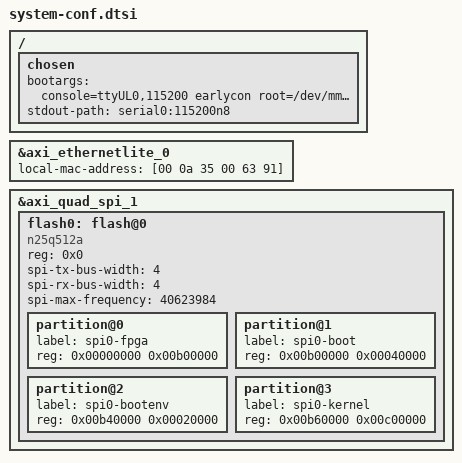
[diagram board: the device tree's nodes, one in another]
/*
 * CAUTION: This file is automatically generated by PetaLinux SDK.
 * DO NOT modify this file
 */


/ {
	chosen {
		bootargs = "console=ttyUL0,115200 earlycon root=/dev/mmcblk0p1 rw rootwait rootfstype=ext4";
		stdout-path = "serial0:115200n8";
	};
};

&axi_ethernetlite_0 {
	local-mac-address = [00 0a 35 00 63 91];
};

&axi_quad_spi_1 {
	#address-cells = <1>;
	#size-cells = <0>;
	flash0: flash@0 {
		compatible = "n25q512a","jedec,spi-nor";
		reg = <0x0>;
		#address-cells = <1>;
		#size-cells = <1>;
		spi-tx-bus-width=<4>;
		spi-rx-bus-width=<4>;
		spi-max-frequency = <40623984>;
		partition@0 {
			label = "spi0-fpga";
			reg = <0x00000000 0x00b00000>;
		};
		partition@1 {
			label = "spi0-boot";
			reg = <0x00b00000 0x00040000>;
		};
		partition@2 {
			label = "spi0-bootenv";
			reg = <0x00b40000 0x00020000>;
		};
		partition@3 {
			label = "spi0-kernel";
			reg = <0x00b60000 0x00c00000>;
		};
	};
};

